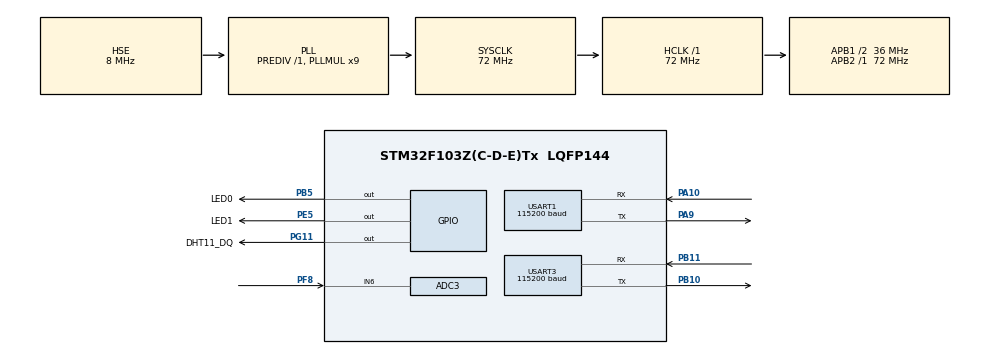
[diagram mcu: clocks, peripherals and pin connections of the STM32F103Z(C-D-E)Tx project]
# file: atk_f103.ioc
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ADC3.Channel-0\#ChannelRegularConversion=ADC_CHANNEL_6
ADC3.NbrOfConversionFlag=1
ADC3.Rank-0\#ChannelRegularConversion=1
ADC3.SamplingTime-0\#ChannelRegularConversion=ADC_SAMPLETIME_239CYCLES_5
Mcu.Family=STM32F1
Mcu.Name=STM32F103Z(C-D-E)Tx
Mcu.Package=LQFP144
NVIC.PriorityGroup=NVIC_PRIORITYGROUP_2
NVIC.USART1_IRQn=true\:2\:0\:false\:false\:true\:true\:true\:true
NVIC.USART3_IRQn=true\:2\:0\:false\:false\:true\:true\:true\:true
OSC_IN.Mode=HSE-External-Oscillator
OSC_IN.Signal=RCC_OSC_IN
OSC_OUT.Mode=HSE-External-Oscillator
OSC_OUT.Signal=RCC_OSC_OUT
PA10.Mode=Asynchronous
PA10.Signal=USART1_RX
PA13.Mode=Serial_Wire
PA13.Signal=SYS_JTMS-SWDIO
PA14.Mode=Serial_Wire
PA14.Signal=SYS_JTCK-SWCLK
PA9.Mode=Asynchronous
PA9.Signal=USART1_TX
PB10.Mode=Asynchronous
PB10.Signal=USART3_TX
PB11.Mode=Asynchronous
PB11.Signal=USART3_RX
PB5.GPIO_Label=LED0
PB5.GPIO_ModeDefaultOutputPP=GPIO_MODE_OUTPUT_PP
PB5.GPIO_Speed=GPIO_SPEED_FREQ_LOW
PB5.PinState=GPIO_PIN_SET
PB5.Signal=GPIO_Output
PE5.GPIO_Label=LED1
PE5.GPIO_ModeDefaultOutputPP=GPIO_MODE_OUTPUT_PP
PE5.GPIO_Speed=GPIO_SPEED_FREQ_LOW
PE5.PinState=GPIO_PIN_SET
PE5.Signal=GPIO_Output
PF8.Mode=IN6
PF8.Signal=ADC3_IN6
PG11.GPIO_Label=DHT11_DQ
PG11.GPIO_ModeDefaultOutputPP=GPIO_MODE_OUTPUT_OD
PG11.GPIO_PuPd=GPIO_PULLUP
PG11.GPIO_Speed=GPIO_SPEED_FREQ_HIGH
PG11.Signal=GPIO_Output
ProjectManager.HeapSize=0x200
ProjectManager.StackSize=0x800
ProjectManager.TargetToolchain=MDK-ARM V5
RCC.ADCPresc=RCC_ADCPCLK2_DIV6
RCC.AHBCLKDivider=RCC_SYSCLK_DIV1
RCC.AHBFreq_Value=72000000
RCC.APB1CLKDivider=RCC_HCLK_DIV2
RCC.APB1Freq_Value=36000000
RCC.APB1TimFreq_Value=72000000
RCC.APB2CLKDivider=RCC_HCLK_DIV1
RCC.APB2Freq_Value=72000000
RCC.APB2TimFreq_Value=72000000
RCC.HCLKFreq_Value=72000000
RCC.PLLMUL=RCC_PLL_MUL9
RCC.PLLSourceVirtual=RCC_PLLSOURCE_HSE
RCC.SYSCLKFreq_VALUE=72000000
RCC.SYSCLKSource=RCC_SYSCLKSOURCE_PLLCLK
RCC.USBFreq_Value=72000000
USART1.BaudRate=115200
USART1.Parity=PARITY_NONE
USART1.StopBits=STOPBITS_1
USART1.VirtualMode=VM_ASYNC
USART1.WordLength=WORDLENGTH_8B
USART3.BaudRate=115200
USART3.Parity=PARITY_NONE
USART3.StopBits=STOPBITS_1
USART3.VirtualMode=VM_ASYNC
USART3.WordLength=WORDLENGTH_8B
board=custom

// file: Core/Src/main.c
/* USER CODE BEGIN Header */
/**
  ******************************************************************************
  * @file           : main.c
  * @brief          : Main program body
  ******************************************************************************
  * @attention
  *
  * Copyright (c) 2026 STMicroelectronics.
  * All rights reserved.
  *
  * This software is licensed under terms that can be found in the LICENSE file
  * in the root directory of this software component.
  * If no LICENSE file comes with this software, it is provided AS-IS.
  *
  ******************************************************************************
  */
/* USER CODE END Header */
#include "main.h"
#include "adc.h"
#include "usart.h"
#include "gpio.h"

/* USER CODE BEGIN Includes */
#include "./App/app_main.h"        /* 应用主入口(全部业务代码在 App/ 与 BSP/ 下) */
/* USER CODE END Includes */

void SystemClock_Config(void);

int main(void)
{

  /* MCU Configuration--------------------------------------------------------*/

  /* Reset of all peripherals, Initializes the Flash interface and the Systick. */
  HAL_Init();

  /* Configure the system clock */
  SystemClock_Config();

  /* Initialize all configured peripherals */
  MX_GPIO_Init();
  MX_ADC3_Init();
  MX_USART1_UART_Init();
  MX_USART3_UART_Init();
  /* USER CODE BEGIN 2 */
  app_main();                       /* 进入应用主循环, 不会返回 */
  /* USER CODE END 2 */

  /* Infinite loop */
  while (1)
  {

  }
}

void SystemClock_Config(void)
{
  RCC_OscInitTypeDef RCC_OscInitStruct = {0};
  RCC_ClkInitTypeDef RCC_ClkInitStruct = {0};
  RCC_PeriphCLKInitTypeDef PeriphClkInit = {0};

  /** Initializes the RCC Oscillators according to the specified parameters
  * in the RCC_OscInitTypeDef structure.
  */
  RCC_OscInitStruct.OscillatorType = RCC_OSCILLATORTYPE_HSE;
  RCC_OscInitStruct.HSEState = RCC_HSE_ON;
  RCC_OscInitStruct.HSEPredivValue = RCC_HSE_PREDIV_DIV1;
  RCC_OscInitStruct.HSIState = RCC_HSI_ON;
  RCC_OscInitStruct.PLL.PLLState = RCC_PLL_ON;
  RCC_OscInitStruct.PLL.PLLSource = RCC_PLLSOURCE_HSE;
  RCC_OscInitStruct.PLL.PLLMUL = RCC_PLL_MUL9;
  if (HAL_RCC_OscConfig(&RCC_OscInitStruct) != HAL_OK)
  {
    Error_Handler();
  }

  /** Initializes the CPU, AHB and APB buses clocks
  */
  RCC_ClkInitStruct.ClockType = RCC_CLOCKTYPE_HCLK|RCC_CLOCKTYPE_SYSCLK
                              |RCC_CLOCKTYPE_PCLK1|RCC_CLOCKTYPE_PCLK2;
  RCC_ClkInitStruct.SYSCLKSource = RCC_SYSCLKSOURCE_PLLCLK;
  RCC_ClkInitStruct.AHBCLKDivider = RCC_SYSCLK_DIV1;
  RCC_ClkInitStruct.APB1CLKDivider = RCC_HCLK_DIV2;
  RCC_ClkInitStruct.APB2CLKDivider = RCC_HCLK_DIV1;

  if (HAL_RCC_ClockConfig(&RCC_ClkInitStruct, FLASH_LATENCY_2) != HAL_OK)
  {
    Error_Handler();
  }
  PeriphClkInit.PeriphClockSelection = RCC_PERIPHCLK_ADC;
  PeriphClkInit.AdcClockSelection = RCC_ADCPCLK2_DIV6;
  if (HAL_RCCEx_PeriphCLKConfig(&PeriphClkInit) != HAL_OK)
  {
    Error_Handler();
  }
}

void Error_Handler(void)
{
  __disable_irq();
  while (1)
  {
  }
}
